# apollo3 register map
Vendor: Ambiq Micro; Series: Apollo; File version: 1.0
CPU: CM4 r1p0, little endian, MPU, FPU, 3 interrupt priority bits
Registers are 32-bit, read-write, reset 0x0 unless marked. A register's access mark holds for its fields unless they carry their own. Offsets are from the block's base; [hi:lo] are bit positions; {n}, {i} and the like mark numbered series; 'fields as' and 'values as' point back to an identical list.

## SCARD — Serial ISO7816
Base 0x40080000
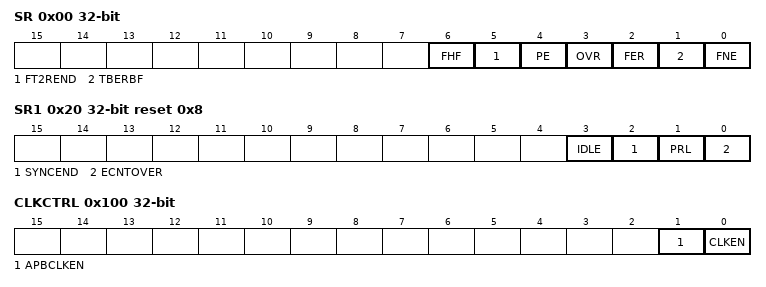
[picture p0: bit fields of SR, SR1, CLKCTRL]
0x00 SR — ISO7816 interrupt status
  [6] FHF — FIFO Half Full.
  [5] FT2REND — TX to RX finished.
  [4] PE — Parity Error.
  [3] OVR — RX FIFO overflow.
  [2] FER — Framing error.
  [1] TBERBF — FIFO empty (transmit) or full (receive).
  [0] FNE — RX FIFO not empty.
0x10 DR — ISO7816 data
  [7:0] DR — Data register.
0x20 SR1 reset 0x8 — ISO7816 interrupt status 1
  [3] IDLE — ISO7816 idle.
  [2] SYNCEND — Write complete synchronization.
  [1] PRL — Card insert/remove.
  [0] ECNTOVER — ETU counter overflow.
0x38 RETXCNTRMI — ISO7816 resent count inquiry
  [3:0] RETXCNTRMI — Resent count inquiry register.
0x100 CLKCTRL — Clock Control
  [1] APBCLKEN — Enable the SCARD APB clock to run continuously.
  [0] CLKEN — Enable the serial source clock for SCARD.

## SECURITY — Security Interfaces
Base 0x40030000
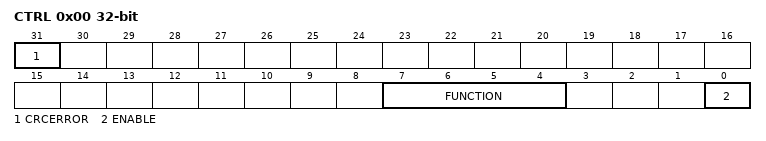
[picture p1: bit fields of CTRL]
0x00 CTRL — Control Register
  [31] CRCERROR — CRC Error Status - Set to 1 if an error occurs during a CRC operation. Cleared when CTRL register is written (with any value). Usually indicates an invalid address range.
  [7:4] FUNCTION — Function Select
    0=CRC32 (Perform CRC32 operation value.)
  [0] ENABLE — Function Enable. Software should set the ENABLE bit to initiate a CRC operation. Hardware will clear the ENABLE bit upon completion.
0x10 SRCADDR — Source Addresss
  [31:0] ADDR — Source Buffer Address. Address may be byte aligned, but the length must be a multiple of 4 bits.
0x20 LEN — Length
  [19:2] LEN — Buffer size (bottom two bits assumed to be zero to ensure a multiple of 4 bytes)
0x30 RESULT — CRC Seed/Result Register
  [31:0] CRC — CRC Seed/Result. Software must seed the CRC with 0xFFFFFFFF before starting a CRC operation (unless the CRC is continued from a previous operation).
0x78 LOCKCTRL — LOCK Control Register
  [7:0] SELECT — LOCK Function Select register.
    1=CUSTOMER_KEY (Unlock Customer Key (access to top half of info0) value.); 0=NONE (Lock Control should be set to NONE when not in use. value.)
0x7C LOCKSTAT — LOCK Status Register
  [31:0] STATUS — LOCK Status register. This register is a bitmask for which resources are currently unlocked. These bits are one-hot per resource.
    1=CUSTOMER_KEY (Customer Key is unlocked (access is granted to top half of info0) value.); 0=NONE (No resources are unlocked value.)
{0x80+4i} KEY{i} (i=0..3)
  [31:0] KEY{i} — Bits [{32i+31}:{32i}] of the 128-bit key should be written to this register. To protect key values, the register always returns 0x00000000.

## VCOMP — Voltage Comparator
Base 0x4000C000
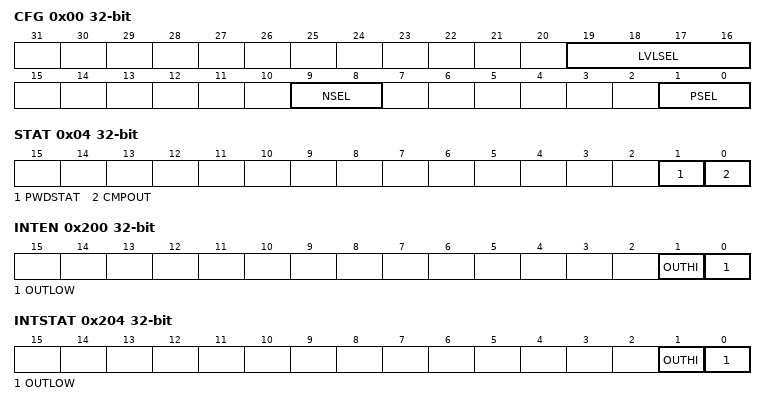
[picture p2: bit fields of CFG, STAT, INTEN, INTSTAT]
0x00 CFG — Configuration Register
  [19:16] LVLSEL — When the reference input NSEL is set to NSEL_DAC, this bitfield selects the voltage level for the negative input to the comparator.
    0=0P58V (Set Reference input to 0.58 Volts. value.); 1=0P77V (Set Reference input to 0.77 Volts. value.); 2=0P97V (Set Reference input to 0.97 Volts. value.); 3=1P16V (Set Reference input to 1.16 Volts. value.); 4=1P35V (Set Reference input to 1.35 Volts. value.); 5=1P55V (Set Reference input to 1.55 Volts. value.); 6=1P74V (Set Reference input to 1.74 Volts. value.); 7=1P93V (Set Reference input to 1.93 Volts. value.); 8=2P13V (Set Reference input to 2.13 Volts. value.); 9=2P32V (Set Reference input to 2.32 Volts. value.); 10=2P51V (Set Reference input to 2.51 Volts. value.); 11=2P71V (Set Reference input to 2.71 Volts. value.); 12=2P90V (Set Reference input to 2.90 Volts. value.); 13=3P09V (Set Reference input to 3.09 Volts. value.); 14=3P29V (Set Reference input to 3.29 Volts. value.); 15=3P48V (Set Reference input to 3.48 Volts. value.)
  [9:8] NSEL — This bitfield selects the negative input to the comparator.
    0=VREFEXT1 (Use external reference 1 for reference input. value.); 1=VREFEXT2 (Use external reference 2 for reference input. value.); 2=VREFEXT3 (Use external reference 3 for reference input. value.); 3=DAC (Use DAC output selected by LVLSEL for reference input. value.)
  [1:0] PSEL — This bitfield selects the positive input to the comparator.
    0=VDDADJ (Use VDDADJ for the positive input. value.); 1=VTEMP (Use the temperature sensor output for the positive input. Note: If this channel is selected for PSEL, the bandap circuit required for temperature comparisons will automatically turn on. The bandgap circuit requires 11us to stabalize. value.); 2=VEXT1 (Use external voltage 0 for positive input. value.); 3=VEXT2 (Use external voltage 1 for positive input. value.)
0x04 STAT — Status Register
  [1] PWDSTAT — This bit indicates the power down state of the voltage comparator.
    1=POWERED_DOWN (The voltage comparator is powered down. value.)
  [0] CMPOUT — This bit is 1 if the positive input of the comparator is greater than the negative input.
    0=VOUT_LOW (The negative input of the comparator is greater than the positive input. value.); 1=VOUT_HIGH (The positive input of the comparator is greater than the negative input. value.)
0x08 PWDKEY — Key Register for Powering Down the Voltage Comparator
  [31:0] PWDKEY — Key register value.
    55=Key (Key value.)
0x200 INTEN — Voltage Comparator Interrupt registers: Enable
  [1] OUTHI — This bit is the vcompout high interrupt.
  [0] OUTLOW — This bit is the vcompout low interrupt.
0x204 INTSTAT — Voltage Comparator Interrupt registers: Status
  fields as INTEN
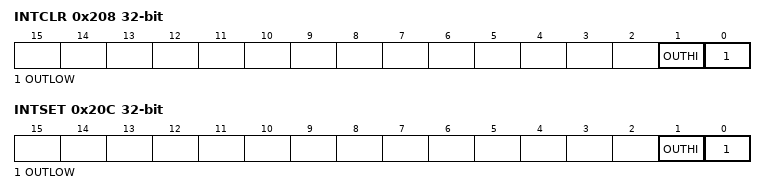
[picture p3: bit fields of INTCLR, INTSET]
0x208 INTCLR — Voltage Comparator Interrupt registers: Clear
  fields as INTEN
0x20C INTSET — Voltage Comparator Interrupt registers: Set
  fields as INTEN

## WDT — Watchdog Timer
Base 0x40024000
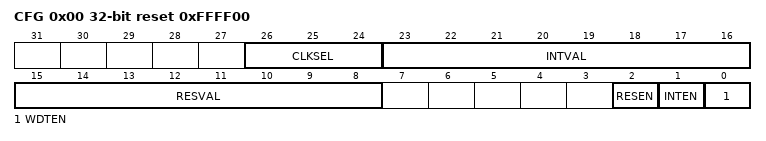
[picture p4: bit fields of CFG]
0x00 CFG reset 0xFFFF00 — Configuration Register
  [26:24] CLKSEL — Select the frequency for the WDT. All values not enumerated below are undefined.
    0=OFF (Low Power Mode. This setting disables the watch dog timer. value.); 1=128HZ (128 Hz LFRC clock. value.); 2=16HZ (16 Hz LFRC clock. value.); 3=1HZ (1 Hz LFRC clock. value.); 4=1_16HZ (1/16th Hz LFRC clock. value.)
  [23:16] INTVAL — This bitfield is the compare value for counter bits 7:0 to generate a watchdog interrupt.
  [15:8] RESVAL — This bitfield is the compare value for counter bits 7:0 to generate a watchdog reset. This will cause a software reset.
  [2] RESEN — This bitfield enables the WDT reset. This needs to be set together with the WDREN bit in REG_RSTGEN_CFG register (in reset gen) to trigger the reset.
  [1] INTEN — This bitfield enables the WDT interrupt. Note : This bit must be set before the interrupt status bit will reflect a watchdog timer expiration. The IER interrupt register must also be enabled for a WDT interrupt to be sent to the NVIC.
  [0] WDTEN — This bitfield enables the WDT.
0x04 RSTRT — Restart the watchdog timer.
  [7:0] RSTRT — Writing 0xB2 to WDTRSTRT restarts the watchdog timer. This is a write only register. Reading this register will only provide all 0.
    178=KEYVALUE (This is the key value to write to WDTRSTRT to restart the WDT. This is a write only register. value.)
0x08 LOCK — Locks the WDT
  [7:0] LOCK — Writing 0x3A locks the watchdog timer. Once locked, the WDTCFG reg cannot be written and WDTEN is set.
    58=KEYVALUE (This is the key value to write to WDTLOCK to lock the WDT. value.)
0x0C COUNT — Current Counter Value for WDT
  [7:0] COUNT — Read-Only current value of the WDT counter
0x200 INTEN — WDT Interrupt register: Enable
  [0] WDTINT — Watchdog Timer Interrupt.
0x204 INTSTAT — WDT Interrupt register: Status
  [0] WDTINT — Watchdog Timer Interrupt.
0x208 INTCLR — WDT Interrupt register: Clear
  [0] WDTINT — Watchdog Timer Interrupt.
0x20C INTSET — WDT Interrupt register: Set
  [0] WDTINT — Watchdog Timer Interrupt.
